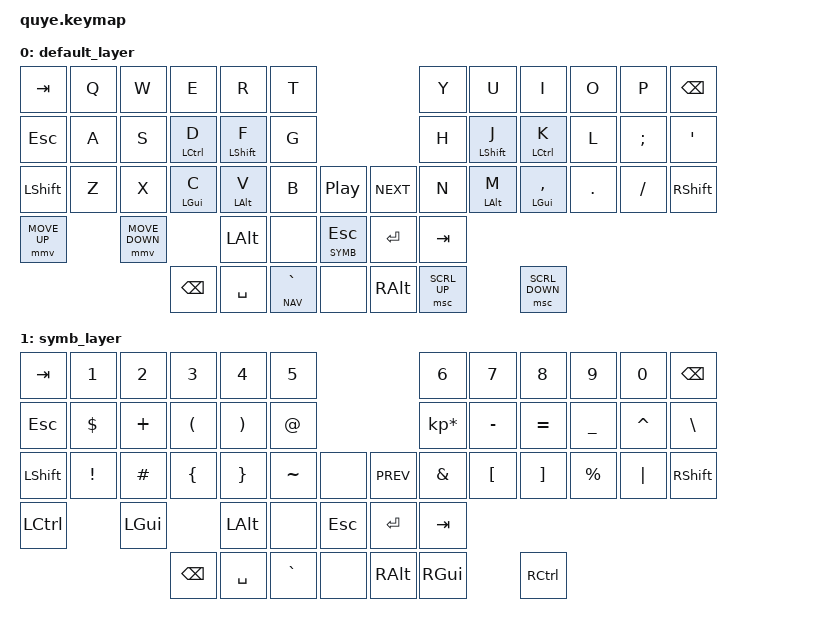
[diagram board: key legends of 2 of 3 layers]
/*
 * Copyright (c) 2020 The ZMK Contributors
 *
 * SPDX-License-Identifier: MIT
 */

#include <behaviors.dtsi>
#include <dt-bindings/zmk/keys.h>
#include <dt-bindings/zmk/bt.h>
#include <dt-bindings/zmk/outputs.h>
#include <dt-bindings/zmk/mouse.h>
#define DEFAULT 0
#define SYMB  1
#define NAV  2
#define MOUSE  3
#define MEDIA  4

#define NAV_GRAVE &lt NAV GRAVE
#define SYMB_ESC &lt SYMB ESC
#define S_F &hht LSHFT F
#define S_J &hht LSHFT J
#define C_D &hht LCTRL D
#define C_K &hht LCTRL K

#define A_V &hht LALT V
#define A_M &hht LALT M
#define G_C &hht LGUI C
#define G_CO &hht LGUI COMMA

/ {

    behaviors {
        hht: home_hold_tap {
            compatible = "zmk,behavior-hold-tap";
            label = "HOME_HOLD_TAP";
            #binding-cells = <2>;
            flavor = "tap-preferred";
            tapping-term-ms = <150>;
            quick-tap-ms = <150>;
            // require-prior-idle-ms = <50>;
            bindings = <&kp>, <&kp>;
        };
        inc_dec_msc: enc_mouse_scroll {
            compatible = "zmk,behavior-sensor-rotate-var";
            #sensor-binding-cells = <2>;
            bindings = <&msc>, <&msc>;
            tap-ms = <100>;
      };
        inc_dec_mmv: enc_mouse_move {
            compatible = "zmk,behavior-sensor-rotate-var";
            #sensor-binding-cells = <2>;
            bindings = <&mmv>, <&mmv>;
            tap-ms = <200>;
      };
    };
       keymap {
                compatible = "zmk,keymap";

                default_layer {
// -----------------------------------------------------------------------------------------
// |  TAB |  Q  |  W  |  E  |  R  |  T  |   |  Y  |  U   |  I  |  O  |  P  | BKSP |
// | CTRL |  A  |  S  |  D  |  F  |  G  |   |  H  |  J   |  K  |  L  |  ;  |  '   |
// | SHFT |  Z  |  X  |  C  |  V  |  B  |   |  N  |  M   |  ,  |  .  |  /  | ESC  |
//                    | GUI | LWR | SPC |   | ENT | RSE  | ALT |
                        bindings = <
   &kp TAB   &kp Q &kp W    &kp E &kp R      &kp T                     &kp Y   &kp U &kp I &kp O   &kp P    &kp BSPC
   &kp ESC   &kp A &kp S    C_D   S_F        &kp G                     &kp H   S_J   C_K   &kp L   &kp SEMI &kp SQT
   &kp LSHFT &kp Z &kp X    G_C   A_V        &kp B &kp C_PP &kp C_NEXT &kp N   A_M   G_CO  &kp DOT &kp FSLH &kp RSHFT
    &mmv MOVE_UP &mmv MOVE_DOWN &kp LALT &none SYMB_ESC &kp RET &kp TAB
                         &kp BSPC &kp SPACE NAV_GRAVE &none &kp RALT  &msc SCRL_UP &msc SCRL_DOWN
                        >;
                        sensor-bindings = <&inc_dec_msc SCRL_DOWN SCRL_UP  &inc_dec_kp C_BRI_UP C_BRI_DN
                                           &inc_dec_kp C_VOL_UP C_VOL_DN &inc_dec_msc SCRL_LEFT SCRL_RIGHT>;
                };
                symb_layer {
// // -----------------------------------------------------------------------------------------
// // |  TAB |  1  |  2  |  3  |  4  |  5  |   |  6  |  7  |  8  |  9  |  0  | BKSP |
// // | BTCLR| BT1 | BT2 | BT3 | BT4 | BT5 |   | LFT | DWN |  UP | RGT |     |      |
// // | SHFT |     |     |     |     |     |   |     |     |     |     |     |      |
// //                    | GUI |     | SPC |   | ENT |     | ALT |
                        bindings = <
&kp TAB &kp N1   &kp N2 &kp N3   &kp N4   &kp N5
                                       &kp N6    &kp N7   &kp N8          &kp N9   &kp N0   &kp BSPC
&kp ESC &kp DLLR &kp PLUS &kp LPAR &kp RPAR &kp AT
                                       &kp KP_MULTIPLY &kp MINUS &kp EQUAL &kp UNDER &kp CARET &kp BSLH
&kp LSHFT  &kp EXCL  &kp  HASH     &kp LBRC  &kp RBRC  &kp TILDE &none
                                       &kp C_PREV  &kp AMPS  &kp LBKT &kp  RBKT  &kp PRCNT &kp PIPE  &kp RSHFT
    &kp LCTRL &kp LGUI &kp LALT &none &kp ESC &kp RET &kp TAB
                         &kp BSPC &kp SPACE &kp GRAVE &none &kp RALT  &kp RGUI   &kp RCTRL
                        >;
                        sensor-bindings = <&inc_dec_mmv MOVE_DOWN MOVE_UP  &inc_dec_kp RIGHT LEFT
                                           &inc_dec_kp C_VOL_UP C_VOL_DN &inc_dec_mmv MOVE_LEFT MOVE_RIGHT>;
                };

                nav_layer {
// // -----------------------------------------------------------------------------------------
// // |  TAB |  !  |  @  |  #  |  $  |  %  |   |  ^  |  &  |  *  |  (  |  )  | BKSP |
// // | CTRL |     |     |     |     |     |   |  -  |  =  |  [  |  ]  |  \  |  `   |
// // | SHFT |     |     |     |     |     |   |  _  |  +  |  {  |  }  | "|" |  ~   |
// //                    | GUI |     | SPC |   | ENT |     | ALT |
                        bindings = <
&kp TAB &kp F1 &kp F2  &kp F3 &kp F4   &kp F5
                                       &kp HOME    &kp PG_DN  &kp PG_UP     &kp END   &none   &kp BSPC
&kp ESC &kp F6 &kp F7 &kp F8 &kp F9 &kp F10
                                       &kp LEFT &kp DOWN &kp UP &kp RIGHT &none &none
&kp LSHFT  &kp F11  &kp  F12  &none  &none  &none &none
                                       &none &bt BT_SEL 0 &bt BT_SEL 1 &bt BT_SEL 2 &bt BT_SEL 3 &bt BT_SEL 4
    &kp LCTRL &kp LGUI &kp LALT &none &kp ESC &kp RET &kp TAB
                         &kp BSPC &kp SPACE &kp GRAVE &none &kp RALT  &kp RGUI   &kp RCTRL
                        >;
                        sensor-bindings = <&inc_dec_mmv MOVE_DOWN MOVE_UP  &inc_dec_kp C_VOL_UP C_VOL_DN
                                           &inc_dec_kp C_VOL_UP C_VOL_DN &inc_dec_mmv MOVE_LEFT MOVE_RIGHT>;
                };
        };
};
